# AC7842x register map
Vendor: AutoChips; Series: AC78; File version: 1.0
CPU: CM4 r0p1, little endian, MPU, FPU, VTOR, 4 interrupt priority bits
Registers are 32-bit, read-write, reset 0x0 unless marked. A register's access mark holds for its fields unless they carry their own. Offsets are from the block's base; [hi:lo] are bit positions; {n}, {i} and the like mark numbered series.

## SPI0 — Serial Peripheral Interface
Base 0x4000C000
Same registers: SPI1 0x4000C800, SPI2 0x4000D000, SPI3 0x4000D800
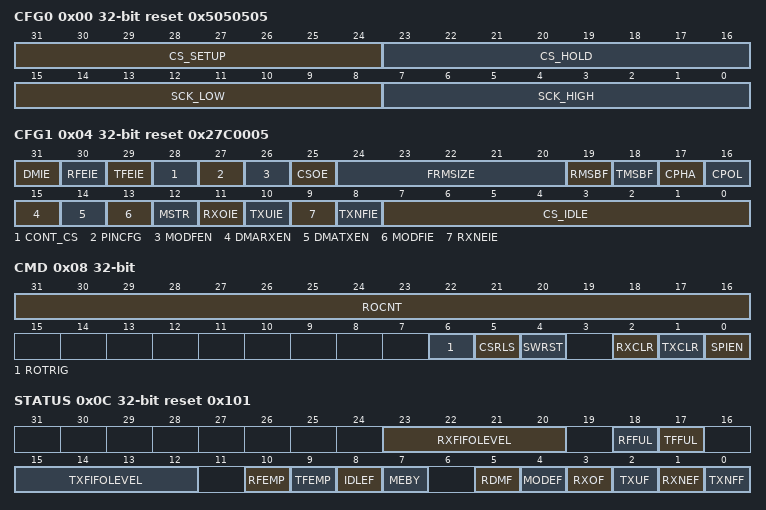
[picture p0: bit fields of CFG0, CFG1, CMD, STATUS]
0x00 CFG0 reset 0x5050505 — SPI Configuration Register 0
  [31:24] CS_SETUP — CS setup count
  [23:16] CS_HOLD — CS hold count
  [15:8] SCK_LOW — SCK low count
  [7:0] SCK_HIGH — SCK high count
0x04 CFG1 reset 0x27C0005 — SPI Configuration Register 1
  [31] DMIE — Data match interrupt enable
    0=False (Disable); 1=True (Enable)
  [30] RFEIE — RX buffer empty interrupt enable
    0=False (Disable); 1=True (Enable)
  [29] TFEIE — TX buffer empty interrupt enable
    0=False (Disable); 1=True (Enable)
  [28] CONT_CS — CS continuous output enable
    0=False (Disable); 1=True (Enable)
  [27] PINCFG — SOUT and SIN pin mode configuration
    0=False (SOUT as master output, SIN as slave output); 1=True (SIN as master output, SOUT as slave output)
  [26] MODFEN — Master mode fault detect enable
    0=False (Disable); 1=True (Enable)
  [25] CSOE — CS hardware output enable
    0=False (Disable); 1=True (Enable)
  [24:20] FRMSIZE — frame size
    {v}=Frame size is 4 bits (v=0..3); {v}=Frame size is {v+1} bits (v=4..31)
  [19] RMSBF — RX MSB first Select
    0=False (RX LSB first); 1=True (RX MSB first)
  [18] TMSBF — TX MSB first Select
    0=False (TX LSB first); 1=True (TX MSB first)
  [17] CPHA — clock phase
    0=False (The first SCK edge capture the data); 1=True (The second SCK edge capture the data)
  [16] CPOL — clock polarity
    0=False (SCK is 0 when idle); 1=True (SCK is 1 when idle)
  [15] DMARXEN — DMA RX channel enable
    0=False (Disable); 1=True (Enable)
  [14] DMATXEN — DMA TX channel enable
    0=False (Disable); 1=True (Enable)
  [13] MODFIE — Master mode fault interrupt enable
    0=False (Disable); 1=True (Enable)
  [12] MSTR — master or slave mode selection
    0=SLAVE (SPI slave mode); 1=MASTER (SPI master mode)
  [11] RXOIE — RX buffer overflow interrupt enable
    0=False (Disable); 1=True (Enable)
  [10] TXUIE — TX buffer underflow interrupt enable
    0=False (Disable); 1=True (Enable)
  [9] RXNEIE — RX buffer not empty interrupt enable
    0=False (Disable); 1=True (Enable)
  [8] TXNFIE — TX buffer not full interrupt enable
    0=False (Disable); 1=True (Enable)
  [7:0] CS_IDLE — CS idle time
0x08 CMD — SPI Command Register
  [31:16] ROCNT — Master RX only mode tranfer count
  [6] ROTRIG — Master RX only mode trigger
    0=False (No effect); 1=True (Trigger read)
  [5] CSRLS — CS release(only valid for CS continuous output)
    0=False (No effect); 1=True (Release CS)
  [4] SWRST — Software reset
    0=False (No effect); 1=True (Reset)
  [2] RXCLR — Clear RX FIFO
    0=False (No effect); 1=True (Clear FIFO)
  [1] TXCLR — Clear TX FIFO
    0=False (No effect); 1=True (Clear FIFO)
  [0] SPIEN — SPI Enable
    0=False (Disable); 1=True (Enable)
0x0C STATUS reset 0x101 — SPI Status Register
  [23:20] RXFIFOLEVEL ro — RX FIFO entry count
  [18] RFFUL ro — RX buffer full flag
    0=False (Not full); 1=True (Full)
  [17] TFFUL ro — TX buffer full flag
    0=False (Not full); 1=True (Full)
  [15:12] TXFIFOLEVEL ro — TX FIFO entry count
  [10] RFEMP ro — RX buffer empty flag
    0=False (Not empty); 1=True (Empty)
  [9] TFEMP ro — TX buffer empty flag
    0=False (Not empty); 1=True (Empty)
  [8] IDLEF ro — SPI module hardware idle flag
    0=False (Not idle); 1=True (Idle)
  [7] MEBY ro — SPI master engine busy flag
    0=False (Transmission finished); 1=True (Transmission not finish)
  [5] RDMF — RX data match flag
    0=False (No RX data match); 1=True (RX data match)
  [4] MODEF ro — Master mode fault flag
    0=False (No Master mode fault); 1=True (Master mode fault)
  [3] RXOF — RX buffer overflow flag
    0=False (No RX overflow); 1=True (RX overflow)
  [2] TXUF — TX buffer underflow flag
    0=False (No TX underflow); 1=True (TX underflow)
  [1] RXNEF ro — RX buffer not empty flag
    0=False (Empty); 1=True (Not empty)
  [0] TXNFF ro — TX buffer not full flag
    0=False (Full); 1=True (Not full)
0x10 DATA — SPI Data Register
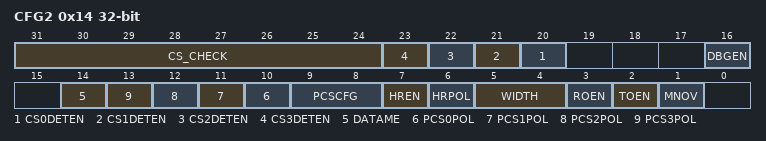
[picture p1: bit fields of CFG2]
0x14 CFG2 reset not defined — SPI configuration register 2
  [31:24] CS_CHECK — Master mode fault check time count
  [n+20] CS{n}DETEN (n=0..3) — CS{n} master mode fault detect enable
    0=False (disable); 1=True (enable)
  [16] DBGEN — Debug Enable
    0=False (SPI disable in debug mode); 1=True (SPI enable in debug mode)
  [14] DATAME — RX data match enable
    0=False (Enable); 1=True (Disable)
  [n+10] PCS{n}POL (n=0..3) — Peripheral Chip Select{n} Polarity
    0=False (Active low); 1=True (Active high)
  [9:8] PCSCFG — Peripheral Chip Select Configuration
    {v}=PCS{v} enable (v=0..3)
  [7] HREN — HREQ enable
    0=False (Disable); 1=True (Enable)
  [6] HRPOL — HREQ polarity
    0=False (Active low); 1=True (Active high)
  [5:4] WIDTH — Transfer width
    0=1 bit; 1=2 bits; 2=4 bits
  [3] ROEN — RX only mode enable
    0=False (Disable); 1=True (Enable)
  [2] TOEN — TX only mode enable
    0=False (Disable); 1=True (Enable)
  [1] MNOV — Master no overflow mode enable
    0=False (Disable); 1=True (Enable)
0x20 DMV reset not defined — SPI data match register
  [31:0] DMV — Data match value
